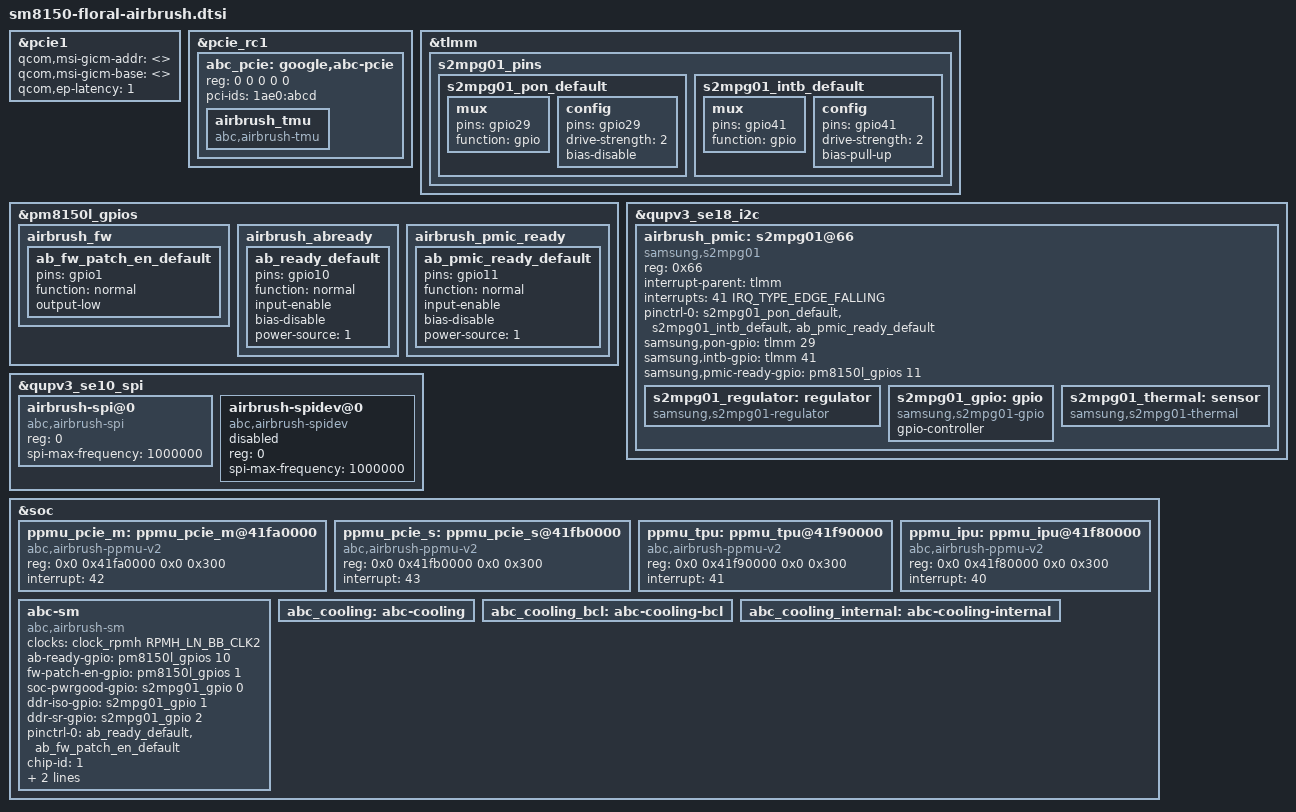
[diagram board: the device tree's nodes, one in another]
/* Copyright (c) 2017, The Linux Foundation. All rights reserved.
 *
 * This program is free software; you can redistribute it and/or modify
 * it under the terms of the GNU General Public License version 2 and
 * only version 2 as published by the Free Software Foundation.
 *
 * This program is distributed in the hope that it will be useful,
 * but WITHOUT ANY WARRANTY; without even the implied warranty of
 * MERCHANTABILITY or FITNESS FOR A PARTICULAR PURPOSE.  See the
 * GNU General Public License for more details.
 */

#include <dt-bindings/interrupt-controller/irq.h>
#include <dt-bindings/gpio/gpio.h>

#include "sm8150-floral-airbrush-trip-points.dtsi"

&pcie1 {
	/* QCOM's GICM implementation is not compatible with Airbrush */
	qcom,msi-gicm-addr = <>;
	qcom,msi-gicm-base = <>;

	/* reduce endpoint reset latency */
	qcom,ep-latency = <1>;
};

&pcie_rc1 {
	abc_pcie: google,abc-pcie {
		reg = <0 0 0 0 0 >;
		pci-ids = "1ae0:abcd";

		airbrush_tmu: airbrush_tmu {
			compatible = "abc,airbrush-tmu";
			#thermal-sensor-cells = <1>;
		};
	};
};

&tlmm {
	s2mpg01_pins {
		s2mpg01_pon_default: s2mpg01_pon_default {
			mux {
				pins = "gpio29";
				function = "gpio";
			};

			config {
				pins = "gpio29";
				drive-strength = <2>;
				bias-disable;
			};
		};

		s2mpg01_intb_default: s2mpg01_intb_default {
			mux {
				pins = "gpio41";
				function = "gpio";
			};

			config {
				pins = "gpio41";
				drive-strength = <2>;
				bias-pull-up;
			};
		};
	};
};

&pm8150l_gpios {
	airbrush_fw {
		ab_fw_patch_en_default: ab_fw_patch_en_default {
			pins = "gpio1";
			function = "normal";
			output-low;
		};
	};

	airbrush_abready {
		ab_ready_default: ab_ready_default {
			pins = "gpio10";
			function = "normal";
			input-enable;
			bias-disable;
			power-source = <1>;	/* 1.8V input supply */
		};
	};

	airbrush_pmic_ready {
		ab_pmic_ready_default: ab_pmic_ready_default {
			pins = "gpio11";
			function = "normal";
			input-enable;
			bias-disable;
			power-source = <1>;	/* 1.8V input supply */
		};
	};
};

&qupv3_se18_i2c {
	status = "okay";
	airbrush_pmic: s2mpg01@66 {
		compatible = "samsung,s2mpg01";
		reg = <0x66>;

		interrupt-parent = <&tlmm>;
		interrupts = <41 IRQ_TYPE_EDGE_FALLING>;
		interrupt-names = "s2mpg01_intb";

		pinctrl-names = "default";
		pinctrl-0 = <&s2mpg01_pon_default
					 &s2mpg01_intb_default
					 &ab_pmic_ready_default>;

		samsung,pon-gpio = <&tlmm 29 0x00>;
		samsung,intb-gpio = <&tlmm 41 0x00>;
		samsung,pmic-ready-gpio = <&pm8150l_gpios 11 GPIO_ACTIVE_HIGH>;

		s2mpg01_regulator: regulator {
			compatible = "samsung,s2mpg01-regulator";
		};

		s2mpg01_gpio: gpio {
			compatible = "samsung,s2mpg01-gpio";
			gpio-controller;
			#gpio-cells = <2>;
		};

		s2mpg01_thermal: sensor {
			compatible = "samsung,s2mpg01-thermal";
			#thermal-sensor-cells = <0>;
		};
	};
};

&qupv3_se10_spi {
	status = "okay";
	airbrush-spi@0 {
		status = "okay";
		compatible = "abc,airbrush-spi";
		reg = <0>;
		spi-max-frequency = <1000000>;
	};
	airbrush-spidev@0 {
		status = "disabled";
		compatible = "abc,airbrush-spidev";
		reg = <0>;
		spi-max-frequency = <1000000>;
	};
};

&soc {

	ppmu_pcie_m: ppmu_pcie_m@41fa0000 {
		compatible = "abc,airbrush-ppmu-v2";
		reg = <0x0 0x41fa0000 0x0 0x300>;
		interrupt = <42>;
		status = "okay";
	};

	ppmu_pcie_s: ppmu_pcie_s@41fb0000 {
		compatible = "abc,airbrush-ppmu-v2";
		reg = <0x0 0x41fb0000 0x0 0x300>;
		interrupt = <43>;
		status = "okay";
	};

	ppmu_tpu: ppmu_tpu@41f90000 {
		compatible = "abc,airbrush-ppmu-v2";
		reg = <0x0 0x41f90000 0x0 0x300>;
		interrupt = <41>;
		status = "okay";
	};

	ppmu_ipu: ppmu_ipu@41f80000 {
		compatible = "abc,airbrush-ppmu-v2";
		reg = <0x0 0x41f80000 0x0 0x300>;
		interrupt = <40>;
		status = "okay";
	};

	abc-sm {
		compatible = "abc,airbrush-sm";

		clocks = <&clock_rpmh RPMH_LN_BB_CLK2>;
		clock-names = "ab_ref";

		/* Provide GPIOs used in Airbrush boot sequence */
		ab-ready-gpio = <&pm8150l_gpios 10 GPIO_ACTIVE_HIGH>;
		fw-patch-en-gpio = <&pm8150l_gpios 1 GPIO_ACTIVE_HIGH>;
		soc-pwrgood-gpio = <&s2mpg01_gpio 0 GPIO_ACTIVE_HIGH>;
		ddr-iso-gpio = <&s2mpg01_gpio 1 GPIO_ACTIVE_HIGH>;
		ddr-sr-gpio = <&s2mpg01_gpio 2 GPIO_ACTIVE_HIGH>;

		pinctrl-names = "default";
		pinctrl-0 = <&ab_ready_default &ab_fw_patch_en_default>;

		chip-id = <1>;

		/* Set optional properties with default values */
		ddrcke-iso-clamp-wr = <0>;
		otp-bypass = <0>;
	};

	abc_cooling: abc-cooling {
		#cooling-cells = <2>;
	};

	abc_cooling_bcl: abc-cooling-bcl {
		#cooling-cells = <2>;
	};

	abc_cooling_internal: abc-cooling-internal {
		#cooling-cells = <2>;
	};
};
